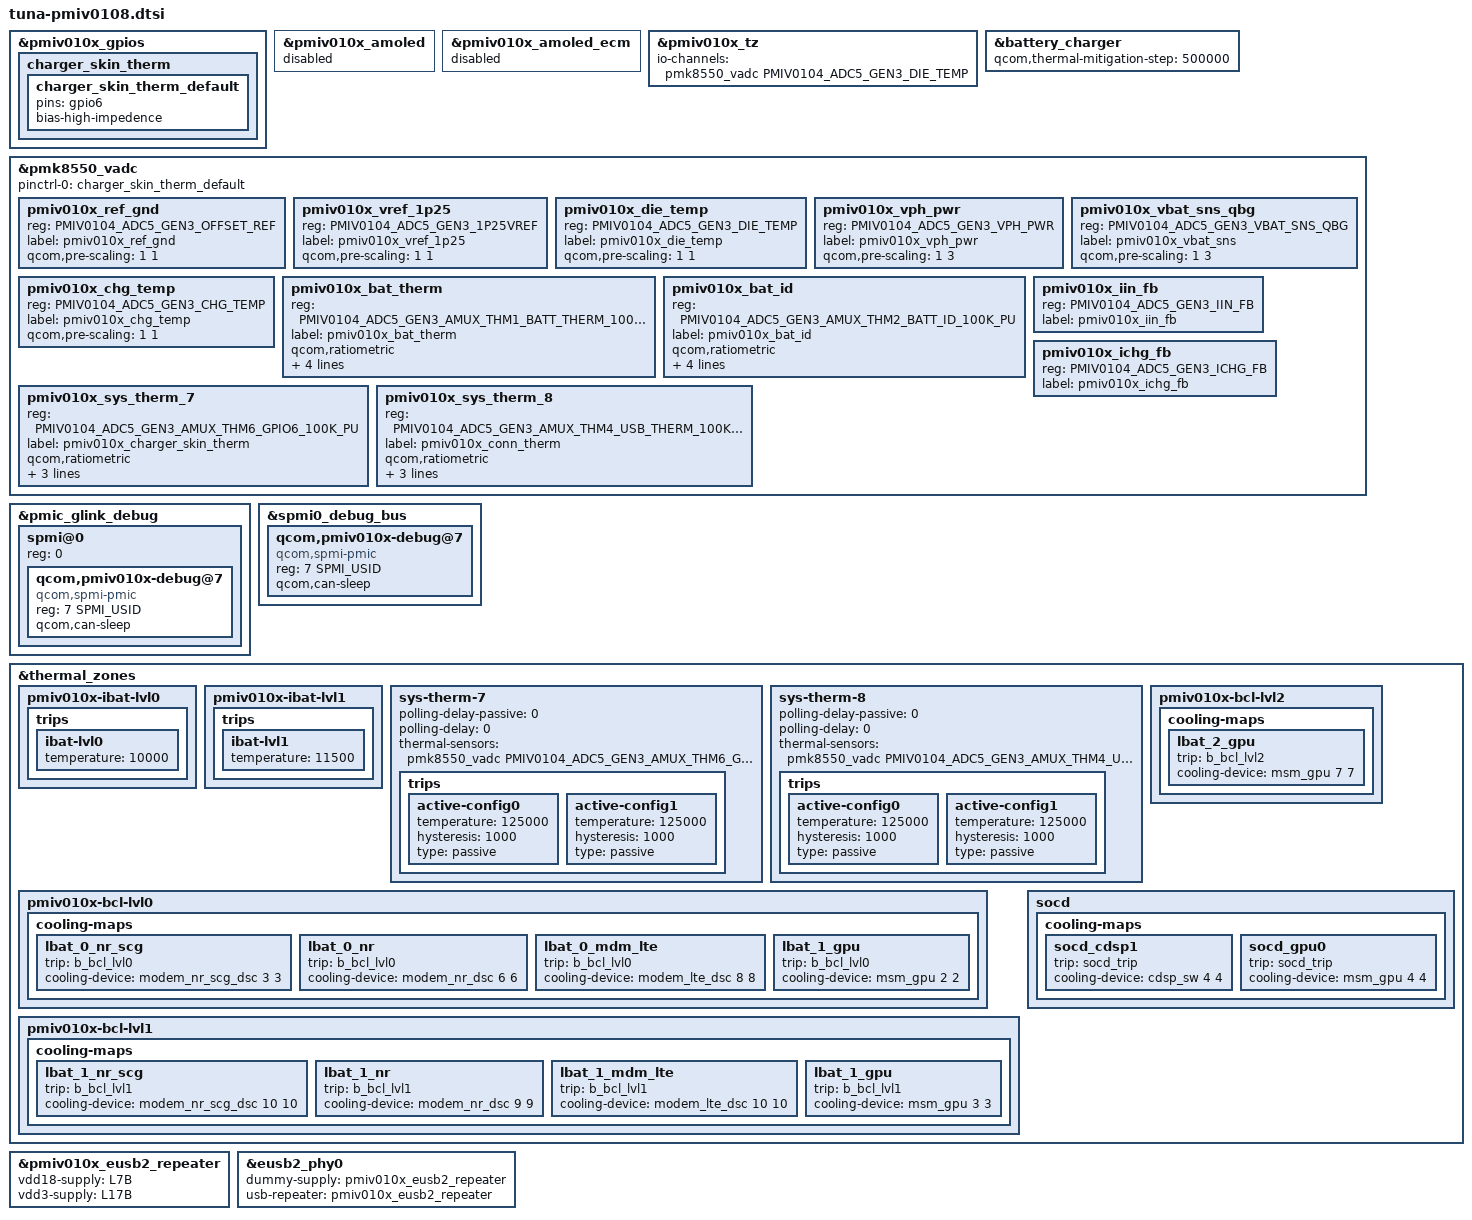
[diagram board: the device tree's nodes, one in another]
// SPDX-License-Identifier: BSD-3-Clause
/*
 * Copyright (c) 2024-2025 Qualcomm Innovation Center, Inc. All rights reserved.
 */

#include <dt-bindings/iio/qcom,spmi-vadc.h>
#include <dt-bindings/iio/qcom,spmi-adc5-gen3-pmiv0104.h>
#include "pmiv010x.dtsi"

&pmiv010x_gpios {
	charger_skin_therm {
		charger_skin_therm_default: charger_skin_therm_default {
			pins = "gpio6";
			bias-high-impedence;
		};
	};
};

&pmiv010x_amoled {
	status= "disabled";
};

&pmiv010x_amoled_ecm {
	status = "disabled";
};

&pmiv010x_tz {
	io-channels = <&pmk8550_vadc PMIV0104_ADC5_GEN3_DIE_TEMP>;
	io-channel-names = "thermal";

};

&battery_charger {
	#cooling-cells = <2>;
	qcom,thermal-mitigation-step = <500000>;
};

&pmk8550_vadc {
	pinctrl-names = "default";
	pinctrl-0 = <&charger_skin_therm_default>;

	pmiv010x_ref_gnd {
		reg = <PMIV0104_ADC5_GEN3_OFFSET_REF>;
		label = "pmiv010x_ref_gnd";
		qcom,pre-scaling = <1 1>;
	};

	pmiv010x_vref_1p25 {
		reg = <PMIV0104_ADC5_GEN3_1P25VREF>;
		label = "pmiv010x_vref_1p25";
		qcom,pre-scaling = <1 1>;
	};

	pmiv010x_die_temp {
		reg = <PMIV0104_ADC5_GEN3_DIE_TEMP>;
		label = "pmiv010x_die_temp";
		qcom,pre-scaling = <1 1>;
	};

	pmiv010x_vph_pwr {
		reg = <PMIV0104_ADC5_GEN3_VPH_PWR>;
		label = "pmiv010x_vph_pwr";
		qcom,pre-scaling = <1 3>;
	};

	pmiv010x_vbat_sns_qbg {
		reg = <PMIV0104_ADC5_GEN3_VBAT_SNS_QBG>;
		label = "pmiv010x_vbat_sns";
		qcom,pre-scaling = <1 3>;
	};

	pmiv010x_chg_temp {
		reg = <PMIV0104_ADC5_GEN3_CHG_TEMP>;
		label = "pmiv010x_chg_temp";
		qcom,pre-scaling = <1 1>;
	};

	pmiv010x_bat_therm {
		reg = <PMIV0104_ADC5_GEN3_AMUX_THM1_BATT_THERM_100K_PU>;
		label = "pmiv010x_bat_therm";
		qcom,ratiometric;
		qcom,hw-settle-time = <200>;
		qcom,pre-scaling = <1 1>;
		qcom,scale-fn-type = <ADC_SCALE_HW_CALIB_PM5_GEN3_BATT_THERM_100K>;
	};

	pmiv010x_bat_id {
		reg = <PMIV0104_ADC5_GEN3_AMUX_THM2_BATT_ID_100K_PU>;
		label = "pmiv010x_bat_id";
		qcom,ratiometric;
		qcom,hw-settle-time = <200>;
		qcom,pre-scaling = <1 1>;
		qcom,scale-fn-type = <ADC_SCALE_HW_CALIB_PM5_GEN3_BATT_ID_100K>;
	};

	pmiv010x_iin_fb {
		reg = <PMIV0104_ADC5_GEN3_IIN_FB>;
		label = "pmiv010x_iin_fb";
	};

	pmiv010x_ichg_fb {
		reg = <PMIV0104_ADC5_GEN3_ICHG_FB>;
		label = "pmiv010x_ichg_fb";
	};

	pmiv010x_sys_therm_7 {
		reg = <PMIV0104_ADC5_GEN3_AMUX_THM6_GPIO6_100K_PU>;
		label = "pmiv010x_charger_skin_therm";
		qcom,ratiometric;
		qcom,hw-settle-time = <200>;
		qcom,pre-scaling = <1 1>;
		qcom,adc-tm-type = <1>;
	};

	pmiv010x_sys_therm_8 {
		reg = <PMIV0104_ADC5_GEN3_AMUX_THM4_USB_THERM_100K_PU>;
		label = "pmiv010x_conn_therm";
		qcom,ratiometric;
		qcom,hw-settle-time = <200>;
		qcom,pre-scaling = <1 1>;
		qcom,adc-tm-type = <1>;
	};
};

&pmic_glink_debug {
	spmi@0 {
		reg = <0>;
		#address-cells = <2>;
		#size-cells = <0>;
		qcom,pmiv010x-debug@7 {
			compatible = "qcom,spmi-pmic";
			reg = <7 SPMI_USID>;
			qcom,can-sleep;
		};
	};
};

&spmi0_debug_bus {
	qcom,pmiv010x-debug@7 {
		compatible = "qcom,spmi-pmic";
		reg = <7 SPMI_USID>;
		#address-cells = <2>;
		#size-cells = <0>;
		qcom,can-sleep;
	};
};

&thermal_zones {
	pmiv010x-ibat-lvl0 {
		trips {
			ibat-lvl0 {
				temperature = <10000>;

			};
		};
	};

	pmiv010x-ibat-lvl1 {
		trips {
			ibat-lvl1 {
				temperature = <11500>;
			};
		};
	};

	sys-therm-7 {
		polling-delay-passive = <0>;
		polling-delay = <0>;
		thermal-sensors = <&pmk8550_vadc PMIV0104_ADC5_GEN3_AMUX_THM6_GPIO6_100K_PU>;
		trips {
			active-config0 {
				temperature = <125000>;
				hysteresis = <1000>;
				type = "passive";
			};

			active-config1 {
				temperature = <125000>;
				hysteresis = <1000>;
				type = "passive";
			};
		};
	};

	sys-therm-8 {
		polling-delay-passive = <0>;
		polling-delay = <0>;
		thermal-sensors = <&pmk8550_vadc PMIV0104_ADC5_GEN3_AMUX_THM4_USB_THERM_100K_PU>;
		trips {
			active-config0 {
				temperature = <125000>;
				hysteresis = <1000>;
				type = "passive";
			};

			active-config1 {
				temperature = <125000>;
				hysteresis = <1000>;
				type = "passive";
			};
		};
	};

	pmiv010x-bcl-lvl0 {
		cooling-maps {
			lbat_0_nr_scg {
				trip = <&b_bcl_lvl0>;
				cooling-device = <&modem_nr_scg_dsc 3 3>;
			};

			lbat_0_nr {
				trip = <&b_bcl_lvl0>;
				cooling-device = <&modem_nr_dsc 6 6>;
			};

			lbat_0_mdm_lte {
				trip = <&b_bcl_lvl0>;
				cooling-device = <&modem_lte_dsc 8 8>;
			};

			lbat_1_gpu {
				trip = <&b_bcl_lvl0>;
				cooling-device = <&msm_gpu 2 2>;
			};
		};
	};

	pmiv010x-bcl-lvl1 {
		cooling-maps {
			lbat_1_nr_scg {
				trip = <&b_bcl_lvl1>;
				cooling-device = <&modem_nr_scg_dsc 10 10>;
			};

			lbat_1_nr {
				trip = <&b_bcl_lvl1>;
				cooling-device = <&modem_nr_dsc 9 9>;
			};

			lbat_1_mdm_lte {
				trip = <&b_bcl_lvl1>;
				cooling-device = <&modem_lte_dsc 10 10>;
			};

			lbat_1_gpu {
				trip = <&b_bcl_lvl1>;
				cooling-device = <&msm_gpu 3 3>;
			};
		};
	};

	pmiv010x-bcl-lvl2 {
		cooling-maps {
			lbat_2_gpu {
				trip = <&b_bcl_lvl2>;
				cooling-device = <&msm_gpu 7 7>;
			};
		};
	};

	socd {
		cooling-maps {
			socd_cdsp1 {
				trip = <&socd_trip>;
				cooling-device = <&cdsp_sw 4 4>;
			};

			socd_gpu0 {
				trip = <&socd_trip>;
				cooling-device = <&msm_gpu 4 4>;
			};
		};
	};
};

&pmiv010x_eusb2_repeater {
	vdd18-supply = <&L7B>;
	vdd3-supply = <&L17B>;
};

&eusb2_phy0 {
	dummy-supply = <&pmiv010x_eusb2_repeater>;
	usb-repeater = <&pmiv010x_eusb2_repeater>;
};
